VERSION "2027-draft-2026-10-23"

NS_ :

BS_:

BU_: Blackbody1 Blackbody2 Blackbody3 ChassisIMU MIKA StrainGaugeFront StrainGaugeRear SuspensionFL SuspensionFR SuspensionRear UprightFL UprightFR UprightRear
VAL_TABLE_ EnableDisable 1 "Enabled" 0 "Disabled" ;
VAL_TABLE_ OnOff 1 "On" 0 "Off" ;
VAL_TABLE_ FaultState 1 "Fault" 0 "OK" ;
VAL_TABLE_ WarningState 1 "Warning" 0 "NoWarning" ;
VAL_TABLE_ DeviceStatus 2 "Waiting" 1 "Fault" 0 "OK" ;
VAL_TABLE_ Permission 1 "Allowed" 0 "NotAllowed" ;
VAL_TABLE_ Connection 1 "Connected" 0 "Disconnected" ;
VAL_TABLE_ ServerConnection 1 "Connected" 0 "Disconnected/Retrying" ;
VAL_TABLE_ Pressed 1 "Pressed" 0 "NotPressed" ;
VAL_TABLE_ Validity 1 "Valid" 0 "Invalid" ;
VAL_TABLE_ Watchdog 1 "TimedOut" 0 "Alive" ;
VAL_TABLE_ NormalAdvanced 1 "Advanced" 0 "Normal" ;
VAL_TABLE_ MotorCommandSource 1 "External" 0 "VCU" ;
VAL_TABLE_ Gear 3 "Invalid" 2 "Reverse" 1 "Forward" 0 "Neutral" ;
VAL_TABLE_ BPSFaultSummary 5 "SMBFault" 4 "PrechargeFault" 3 "ContactorRelayFault" 2 "EmergencyStop" 1 "SetpointFault" 0 "OK" ;
VAL_TABLE_ VCUState 7 "VehicleNotReady" 6 "Disabled" 5 "CruiseControl" 4 "Regen" 3 "ReverseDrive" 2 "NeutralDrive" 1 "ForwardDrive" 0 "Init" ;
VAL_TABLE_ ChargeState 2 "Charging" 1 "Standby" 0 "Disabled" ;
VAL_TABLE_ EVSEState 5 "F_EVSEFault" 4 "E_Fault" 3 "D_VentilationRequired" 2 "C_ChargingReady" 1 "B_Connected" 0 "A_Disconnected" ;
VAL_TABLE_ GPSAntennaState 3 "Unknown" 2 "ShortCircuit" 1 "OpenCircuit" 0 "OK" ;
VAL_TABLE_ GPSFix 2 "Fix3D" 1 "Fix2D" 0 "NoFix" ;
VAL_TABLE_ CellularTechnology 4 "Other" 3 "NB_IoT" 2 "LTE_M" 1 "LTE" 0 "None" ;
VAL_TABLE_ TPEEControlMode 2 "ConstantInputVoltage" 1 "PerturbAndObserve" 0 "Disabled" ;
VAL_TABLE_ TPEEOperatingMode 7 "Fault" 6 "MinimumInputVoltage" 5 "TemperatureDerating" 4 "ConstantOutputCurrent" 3 "ConstantOutputVoltage" 2 "MinimumInputCurrent" 1 "ConstantInputCurrent" 0 "ConstantInputVoltage" ;
VAL_TABLE_ TPEEFault 8 "Fault" 7 "PhaseOverCurrent" 6 "InputUnderCurrent" 5 "InputOverCurrent" 4 "OutputOverCurrent" 3 "OutputOverVoltage" 2 "InputOverVoltage" 1 "ConfigurationError" 0 "OK" ;
VAL_TABLE_ LWSCalibration 1 "Calibrated" 0 "NotCalibrated" ;
VAL_TABLE_ LWSTrim 1 "Trimmed" 0 "NotTrimmed" ;
VAL_TABLE_ LWSCommand 5 "ResetCalibration" 3 "SetAngleZero" ;
VAL_TABLE_ ElconControl 1 "Disable" 0 "Charge" ;
VAL_TABLE_ ElconMuxPage 5 "Page5" 4 "Page4" 3 "Page3" 2 "Page2" 1 "Page1" ;

BO_ 1568 TimestampSync: 2 MIKA
 SG_ Timestamp : 0|16@1+ (1,0) [0|65535] "" Vector__XXX

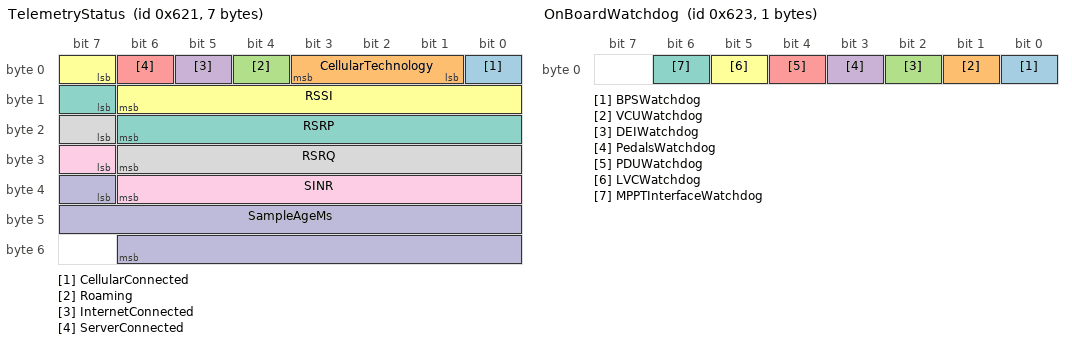
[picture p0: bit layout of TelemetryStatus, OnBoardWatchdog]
BO_ 1569 TelemetryStatus: 7 MIKA
 SG_ CellularConnected : 0|1@1+ (1,0) [0.0|1.0] "" Vector__XXX
 SG_ CellularTechnology : 1|3@1+ (1,0) [0.0|7.0] "" Vector__XXX
 SG_ Roaming : 4|1@1+ (1,0) [0.0|1.0] "" Vector__XXX
 SG_ InternetConnected : 5|1@1+ (1,0) [0.0|1.0] "" Vector__XXX
 SG_ ServerConnected : 6|1@1+ (1,0) [0|1] "" Vector__XXX
 SG_ RSSI : 7|8@1- (1,0) [-128.0|127.0] "dBm" Vector__XXX
 SG_ RSRP : 15|8@1- (1,0) [-128.0|127.0] "dBm" Vector__XXX
 SG_ RSRQ : 23|8@1- (0.5,0) [-64.0|63.5] "dB" Vector__XXX
 SG_ SINR : 31|8@1- (0.5,0) [-64.0|63.5] "dB" Vector__XXX
 SG_ SampleAgeMs : 39|16@1+ (1,0) [0|65535] "ms" Vector__XXX

BO_ 1570 GPSData: 20 MIKA
 SG_ GPSAntennaState : 0|2@1+ (1,0) [0.0|3.0] "" Vector__XXX
 SG_ GPSFix : 2|2@1+ (1,0) [0.0|3.0] "" Vector__XXX
 SG_ GPSLongitude : 4|32@1- (1e-06,0) [-180|180] "deg" Vector__XXX
 SG_ GPSLatitude : 36|32@1- (1e-06,0) [-90|90] "deg" Vector__XXX
 SG_ GPSSpeed : 68|16@1+ (0.01,0) [0.0|655.35] "m/s" Vector__XXX
 SG_ GPSHeading : 84|16@1+ (0.01,0) [0|359.99] "deg" Vector__XXX
 SG_ GPSAltitude : 100|16@1- (0.1,0) [-3276.8|3276.7] "m" Vector__XXX
 SG_ SatellitesInUse : 116|8@1+ (1,0) [0.0|255.0] "" Vector__XXX
 SG_ SampleAgeMs : 124|16@1+ (1,0) [0|65535] "ms" Vector__XXX

BO_ 1571 OnBoardWatchdog: 1 MIKA
 SG_ BPSWatchdog : 0|1@1+ (1,0) [0.0|1.0] "" Vector__XXX
 SG_ VCUWatchdog : 1|1@1+ (1,0) [0.0|1.0] "" Vector__XXX
 SG_ DEIWatchdog : 2|1@1+ (1,0) [0.0|1.0] "" Vector__XXX
 SG_ PedalsWatchdog : 3|1@1+ (1,0) [0.0|1.0] "" Vector__XXX
 SG_ PDUWatchdog : 4|1@1+ (1,0) [0.0|1.0] "" Vector__XXX
 SG_ LVCWatchdog : 5|1@1+ (1,0) [0.0|1.0] "" Vector__XXX
 SG_ MPPTInterfaceWatchdog : 6|1@1+ (1,0) [0.0|1.0] "" Vector__XXX

BO_ 1584 ChassisAccelerationData: 32 ChassisIMU
 SG_ Timestamp : 0|16@1+ (1,0) [0|65535] "" Vector__XXX
 SG_ SampleIntervalTicks : 16|16@1+ (1,0) [1|65535.0] "" Vector__XXX
 SG_ AccelerationX1 : 32|13@1- (0.001,0) [-4.096|4.095] "g" Vector__XXX
 SG_ AccelerationX2 : 45|13@1- (0.001,0) [-4.096|4.095] "g" Vector__XXX
 SG_ AccelerationX3 : 58|13@1- (0.001,0) [-4.096|4.095] "g" Vector__XXX
 SG_ AccelerationX4 : 71|13@1- (0.001,0) [-4.096|4.095] "g" Vector__XXX
 SG_ AccelerationXAverage : 84|13@1- (0.001,0) [-4.096|4.095] "g" Vector__XXX
 SG_ AccelerationY1 : 97|13@1- (0.001,0) [-4.096|4.095] "g" Vector__XXX
 SG_ AccelerationY2 : 110|13@1- (0.001,0) [-4.096|4.095] "g" Vector__XXX
 SG_ AccelerationY3 : 123|13@1- (0.001,0) [-4.096|4.095] "g" Vector__XXX
 SG_ AccelerationY4 : 136|13@1- (0.001,0) [-4.096|4.095] "g" Vector__XXX
 SG_ AccelerationYAverage : 149|13@1- (0.001,0) [-4.096|4.095] "g" Vector__XXX
 SG_ AccelerationZ1 : 162|13@1- (0.001,0) [-4.096|4.095] "g" Vector__XXX
 SG_ AccelerationZ2 : 175|13@1- (0.001,0) [-4.096|4.095] "g" Vector__XXX
 SG_ AccelerationZ3 : 188|13@1- (0.001,0) [-4.096|4.095] "g" Vector__XXX
 SG_ AccelerationZ4 : 201|13@1- (0.001,0) [-4.096|4.095] "g" Vector__XXX
 SG_ AccelerationZAverage : 214|13@1- (0.001,0) [-4.096|4.095] "g" Vector__XXX
 SG_ SampleAgeMs : 227|16@1+ (1,0) [0|65535] "ms" Vector__XXX

BO_ 1585 ChassisGyroData: 48 ChassisIMU
 SG_ Timestamp : 0|16@1+ (1,0) [0|65535] "" Vector__XXX
 SG_ SampleIntervalTicks : 16|16@1+ (1,0) [1|65535.0] "" Vector__XXX
 SG_ GyroX1 : 32|16@1- (0.02,0) [-655.36|655.34] "deg/s" Vector__XXX
 SG_ GyroX2 : 48|16@1- (0.02,0) [-655.36|655.34] "deg/s" Vector__XXX
 SG_ GyroX3 : 64|16@1- (0.02,0) [-655.36|655.34] "deg/s" Vector__XXX
 SG_ GyroX4 : 80|16@1- (0.02,0) [-655.36|655.34] "deg/s" Vector__XXX
 SG_ GyroXAverage : 96|16@1- (0.02,0) [-655.36|655.34] "deg/s" Vector__XXX
 SG_ GyroY1 : 112|16@1- (0.02,0) [-655.36|655.34] "deg/s" Vector__XXX
 SG_ GyroY2 : 128|16@1- (0.02,0) [-655.36|655.34] "deg/s" Vector__XXX
 SG_ GyroY3 : 144|16@1- (0.02,0) [-655.36|655.34] "deg/s" Vector__XXX
 SG_ GyroY4 : 160|16@1- (0.02,0) [-655.36|655.34] "deg/s" Vector__XXX
 SG_ GyroYAverage : 176|16@1- (0.02,0) [-655.36|655.34] "deg/s" Vector__XXX
 SG_ GyroZ1 : 192|16@1- (0.02,0) [-655.36|655.34] "deg/s" Vector__XXX
 SG_ GyroZ2 : 208|16@1- (0.02,0) [-655.36|655.34] "deg/s" Vector__XXX
 SG_ GyroZ3 : 224|16@1- (0.02,0) [-655.36|655.34] "deg/s" Vector__XXX
 SG_ GyroZ4 : 240|16@1- (0.02,0) [-655.36|655.34] "deg/s" Vector__XXX
 SG_ GyroZAverage : 256|16@1- (0.02,0) [-655.36|655.34] "deg/s" Vector__XXX
 SG_ SampleAgeMs : 272|16@1+ (1,0) [0|65535] "ms" Vector__XXX

BO_ 1586 ChassisMagnetometerData: 32 ChassisIMU
 SG_ Timestamp : 0|16@1+ (1,0) [0|65535] "" Vector__XXX
 SG_ SampleIntervalTicks : 16|16@1+ (1,0) [1|65535.0] "" Vector__XXX
 SG_ MagneticFieldX1 : 32|12@1- (0.15,0) [-307.2|307.05] "uT" Vector__XXX
 SG_ MagneticFieldX2 : 44|12@1- (0.15,0) [-307.2|307.05] "uT" Vector__XXX
 SG_ MagneticFieldX3 : 56|12@1- (0.15,0) [-307.2|307.05] "uT" Vector__XXX
 SG_ MagneticFieldX4 : 68|12@1- (0.15,0) [-307.2|307.05] "uT" Vector__XXX
 SG_ MagneticFieldXAverage : 80|12@1- (0.15,0) [-307.2|307.05] "uT" Vector__XXX
 SG_ MagneticFieldY1 : 92|12@1- (0.15,0) [-307.2|307.05] "uT" Vector__XXX
 SG_ MagneticFieldY2 : 104|12@1- (0.15,0) [-307.2|307.05] "uT" Vector__XXX
 SG_ MagneticFieldY3 : 116|12@1- (0.15,0) [-307.2|307.05] "uT" Vector__XXX
 SG_ MagneticFieldY4 : 128|12@1- (0.15,0) [-307.2|307.05] "uT" Vector__XXX
 SG_ MagneticFieldYAverage : 140|12@1- (0.15,0) [-307.2|307.05] "uT" Vector__XXX
 SG_ MagneticFieldZ1 : 152|12@1- (0.15,0) [-307.2|307.05] "uT" Vector__XXX
 SG_ MagneticFieldZ2 : 164|12@1- (0.15,0) [-307.2|307.05] "uT" Vector__XXX
 SG_ MagneticFieldZ3 : 176|12@1- (0.15,0) [-307.2|307.05] "uT" Vector__XXX
 SG_ MagneticFieldZ4 : 188|12@1- (0.15,0) [-307.2|307.05] "uT" Vector__XXX
 SG_ MagneticFieldZAverage : 200|12@1- (0.15,0) [-307.2|307.05] "uT" Vector__XXX
 SG_ SampleAgeMs : 212|16@1+ (1,0) [0|65535] "ms" Vector__XXX

BO_ 1600 UprightFRAccelerationData: 48 UprightFR
 SG_ Timestamp : 0|16@1+ (1,0) [0|65535] "" Vector__XXX
 SG_ SampleIntervalTicks : 16|16@1+ (1,0) [1|65535.0] "" Vector__XXX
 SG_ AccelerationX1 : 32|15@1- (0.001,0) [-16.384|16.383] "g" Vector__XXX
 SG_ AccelerationX2 : 47|15@1- (0.001,0) [-16.384|16.383] "g" Vector__XXX
 SG_ AccelerationX3 : 62|15@1- (0.001,0) [-16.384|16.383] "g" Vector__XXX
 SG_ AccelerationX4 : 77|15@1- (0.001,0) [-16.384|16.383] "g" Vector__XXX
 SG_ AccelerationXAverage : 92|15@1- (0.001,0) [-16.384|16.383] "g" Vector__XXX
 SG_ AccelerationY1 : 107|15@1- (0.001,0) [-16.384|16.383] "g" Vector__XXX
 SG_ AccelerationY2 : 122|15@1- (0.001,0) [-16.384|16.383] "g" Vector__XXX
 SG_ AccelerationY3 : 137|15@1- (0.001,0) [-16.384|16.383] "g" Vector__XXX
 SG_ AccelerationY4 : 152|15@1- (0.001,0) [-16.384|16.383] "g" Vector__XXX
 SG_ AccelerationYAverage : 167|15@1- (0.001,0) [-16.384|16.383] "g" Vector__XXX
 SG_ AccelerationZ1 : 182|15@1- (0.001,0) [-16.384|16.383] "g" Vector__XXX
 SG_ AccelerationZ2 : 197|15@1- (0.001,0) [-16.384|16.383] "g" Vector__XXX
 SG_ AccelerationZ3 : 212|15@1- (0.001,0) [-16.384|16.383] "g" Vector__XXX
 SG_ AccelerationZ4 : 227|15@1- (0.001,0) [-16.384|16.383] "g" Vector__XXX
 SG_ AccelerationZAverage : 242|15@1- (0.001,0) [-16.384|16.383] "g" Vector__XXX
 SG_ SampleAgeMs : 257|16@1+ (1,0) [0|65535] "ms" Vector__XXX

BO_ 1601 UprightFRGyroData: 48 UprightFR
 SG_ Timestamp : 0|16@1+ (1,0) [0|65535] "" Vector__XXX
 SG_ SampleIntervalTicks : 16|16@1+ (1,0) [1|65535.0] "" Vector__XXX
 SG_ GyroX1 : 32|16@1- (0.02,0) [-655.36|655.34] "deg/s" Vector__XXX
 SG_ GyroX2 : 48|16@1- (0.02,0) [-655.36|655.34] "deg/s" Vector__XXX
 SG_ GyroX3 : 64|16@1- (0.02,0) [-655.36|655.34] "deg/s" Vector__XXX
 SG_ GyroX4 : 80|16@1- (0.02,0) [-655.36|655.34] "deg/s" Vector__XXX
 SG_ GyroXAverage : 96|16@1- (0.02,0) [-655.36|655.34] "deg/s" Vector__XXX
 SG_ GyroY1 : 112|16@1- (0.02,0) [-655.36|655.34] "deg/s" Vector__XXX
 SG_ GyroY2 : 128|16@1- (0.02,0) [-655.36|655.34] "deg/s" Vector__XXX
 SG_ GyroY3 : 144|16@1- (0.02,0) [-655.36|655.34] "deg/s" Vector__XXX
 SG_ GyroY4 : 160|16@1- (0.02,0) [-655.36|655.34] "deg/s" Vector__XXX
 SG_ GyroYAverage : 176|16@1- (0.02,0) [-655.36|655.34] "deg/s" Vector__XXX
 SG_ GyroZ1 : 192|16@1- (0.02,0) [-655.36|655.34] "deg/s" Vector__XXX
 SG_ GyroZ2 : 208|16@1- (0.02,0) [-655.36|655.34] "deg/s" Vector__XXX
 SG_ GyroZ3 : 224|16@1- (0.02,0) [-655.36|655.34] "deg/s" Vector__XXX
 SG_ GyroZ4 : 240|16@1- (0.02,0) [-655.36|655.34] "deg/s" Vector__XXX
 SG_ GyroZAverage : 256|16@1- (0.02,0) [-655.36|655.34] "deg/s" Vector__XXX
 SG_ SampleAgeMs : 272|16@1+ (1,0) [0|65535] "ms" Vector__XXX

BO_ 1602 UprightFRWheelSpeedData: 16 UprightFR
 SG_ Timestamp : 0|16@1+ (1,0) [0|65535] "" Vector__XXX
 SG_ SampleIntervalTicks : 16|16@1+ (1,0) [1|65535.0] "" Vector__XXX
 SG_ WheelRPM1 : 32|12@1+ (0.5,0) [0.0|2047.5] "rpm" Vector__XXX
 SG_ WheelRPM2 : 44|12@1+ (0.5,0) [0.0|2047.5] "rpm" Vector__XXX
 SG_ WheelRPM3 : 56|12@1+ (0.5,0) [0.0|2047.5] "rpm" Vector__XXX
 SG_ WheelRPM4 : 68|12@1+ (0.5,0) [0.0|2047.5] "rpm" Vector__XXX
 SG_ WheelRPMAverage : 80|12@1+ (0.5,0) [0.0|2047.5] "rpm" Vector__XXX
 SG_ SampleAgeMs : 92|16@1+ (1,0) [0|65535] "ms" Vector__XXX

BO_ 1616 UprightFLAccelerationData: 48 UprightFL
 SG_ Timestamp : 0|16@1+ (1,0) [0|65535] "" Vector__XXX
 SG_ SampleIntervalTicks : 16|16@1+ (1,0) [1|65535.0] "" Vector__XXX
 SG_ AccelerationX1 : 32|15@1- (0.001,0) [-16.384|16.383] "g" Vector__XXX
 SG_ AccelerationX2 : 47|15@1- (0.001,0) [-16.384|16.383] "g" Vector__XXX
 SG_ AccelerationX3 : 62|15@1- (0.001,0) [-16.384|16.383] "g" Vector__XXX
 SG_ AccelerationX4 : 77|15@1- (0.001,0) [-16.384|16.383] "g" Vector__XXX
 SG_ AccelerationXAverage : 92|15@1- (0.001,0) [-16.384|16.383] "g" Vector__XXX
 SG_ AccelerationY1 : 107|15@1- (0.001,0) [-16.384|16.383] "g" Vector__XXX
 SG_ AccelerationY2 : 122|15@1- (0.001,0) [-16.384|16.383] "g" Vector__XXX
 SG_ AccelerationY3 : 137|15@1- (0.001,0) [-16.384|16.383] "g" Vector__XXX
 SG_ AccelerationY4 : 152|15@1- (0.001,0) [-16.384|16.383] "g" Vector__XXX
 SG_ AccelerationYAverage : 167|15@1- (0.001,0) [-16.384|16.383] "g" Vector__XXX
 SG_ AccelerationZ1 : 182|15@1- (0.001,0) [-16.384|16.383] "g" Vector__XXX
 SG_ AccelerationZ2 : 197|15@1- (0.001,0) [-16.384|16.383] "g" Vector__XXX
 SG_ AccelerationZ3 : 212|15@1- (0.001,0) [-16.384|16.383] "g" Vector__XXX
 SG_ AccelerationZ4 : 227|15@1- (0.001,0) [-16.384|16.383] "g" Vector__XXX
 SG_ AccelerationZAverage : 242|15@1- (0.001,0) [-16.384|16.383] "g" Vector__XXX
 SG_ SampleAgeMs : 257|16@1+ (1,0) [0|65535] "ms" Vector__XXX

BO_ 1617 UprightFLGyroData: 48 UprightFL
 SG_ Timestamp : 0|16@1+ (1,0) [0|65535] "" Vector__XXX
 SG_ SampleIntervalTicks : 16|16@1+ (1,0) [1|65535.0] "" Vector__XXX
 SG_ GyroX1 : 32|16@1- (0.02,0) [-655.36|655.34] "deg/s" Vector__XXX
 SG_ GyroX2 : 48|16@1- (0.02,0) [-655.36|655.34] "deg/s" Vector__XXX
 SG_ GyroX3 : 64|16@1- (0.02,0) [-655.36|655.34] "deg/s" Vector__XXX
 SG_ GyroX4 : 80|16@1- (0.02,0) [-655.36|655.34] "deg/s" Vector__XXX
 SG_ GyroXAverage : 96|16@1- (0.02,0) [-655.36|655.34] "deg/s" Vector__XXX
 SG_ GyroY1 : 112|16@1- (0.02,0) [-655.36|655.34] "deg/s" Vector__XXX
 SG_ GyroY2 : 128|16@1- (0.02,0) [-655.36|655.34] "deg/s" Vector__XXX
 SG_ GyroY3 : 144|16@1- (0.02,0) [-655.36|655.34] "deg/s" Vector__XXX
 SG_ GyroY4 : 160|16@1- (0.02,0) [-655.36|655.34] "deg/s" Vector__XXX
 SG_ GyroYAverage : 176|16@1- (0.02,0) [-655.36|655.34] "deg/s" Vector__XXX
 SG_ GyroZ1 : 192|16@1- (0.02,0) [-655.36|655.34] "deg/s" Vector__XXX
 SG_ GyroZ2 : 208|16@1- (0.02,0) [-655.36|655.34] "deg/s" Vector__XXX
 SG_ GyroZ3 : 224|16@1- (0.02,0) [-655.36|655.34] "deg/s" Vector__XXX
 SG_ GyroZ4 : 240|16@1- (0.02,0) [-655.36|655.34] "deg/s" Vector__XXX
 SG_ GyroZAverage : 256|16@1- (0.02,0) [-655.36|655.34] "deg/s" Vector__XXX
 SG_ SampleAgeMs : 272|16@1+ (1,0) [0|65535] "ms" Vector__XXX

BO_ 1618 UprightFLWheelSpeedData: 16 UprightFL
 SG_ Timestamp : 0|16@1+ (1,0) [0|65535] "" Vector__XXX
 SG_ SampleIntervalTicks : 16|16@1+ (1,0) [1|65535.0] "" Vector__XXX
 SG_ WheelRPM1 : 32|12@1+ (0.5,0) [0.0|2047.5] "rpm" Vector__XXX
 SG_ WheelRPM2 : 44|12@1+ (0.5,0) [0.0|2047.5] "rpm" Vector__XXX
 SG_ WheelRPM3 : 56|12@1+ (0.5,0) [0.0|2047.5] "rpm" Vector__XXX
 SG_ WheelRPM4 : 68|12@1+ (0.5,0) [0.0|2047.5] "rpm" Vector__XXX
 SG_ WheelRPMAverage : 80|12@1+ (0.5,0) [0.0|2047.5] "rpm" Vector__XXX
 SG_ SampleAgeMs : 92|16@1+ (1,0) [0|65535] "ms" Vector__XXX

BO_ 1632 UprightRearAccelerationData: 48 UprightRear
 SG_ Timestamp : 0|16@1+ (1,0) [0|65535] "" Vector__XXX
 SG_ SampleIntervalTicks : 16|16@1+ (1,0) [1|65535.0] "" Vector__XXX
 SG_ AccelerationX1 : 32|15@1- (0.001,0) [-16.384|16.383] "g" Vector__XXX
 SG_ AccelerationX2 : 47|15@1- (0.001,0) [-16.384|16.383] "g" Vector__XXX
 SG_ AccelerationX3 : 62|15@1- (0.001,0) [-16.384|16.383] "g" Vector__XXX
 SG_ AccelerationX4 : 77|15@1- (0.001,0) [-16.384|16.383] "g" Vector__XXX
 SG_ AccelerationXAverage : 92|15@1- (0.001,0) [-16.384|16.383] "g" Vector__XXX
 SG_ AccelerationY1 : 107|15@1- (0.001,0) [-16.384|16.383] "g" Vector__XXX
 SG_ AccelerationY2 : 122|15@1- (0.001,0) [-16.384|16.383] "g" Vector__XXX
 SG_ AccelerationY3 : 137|15@1- (0.001,0) [-16.384|16.383] "g" Vector__XXX
 SG_ AccelerationY4 : 152|15@1- (0.001,0) [-16.384|16.383] "g" Vector__XXX
 SG_ AccelerationYAverage : 167|15@1- (0.001,0) [-16.384|16.383] "g" Vector__XXX
 SG_ AccelerationZ1 : 182|15@1- (0.001,0) [-16.384|16.383] "g" Vector__XXX
 SG_ AccelerationZ2 : 197|15@1- (0.001,0) [-16.384|16.383] "g" Vector__XXX
 SG_ AccelerationZ3 : 212|15@1- (0.001,0) [-16.384|16.383] "g" Vector__XXX
 SG_ AccelerationZ4 : 227|15@1- (0.001,0) [-16.384|16.383] "g" Vector__XXX
 SG_ AccelerationZAverage : 242|15@1- (0.001,0) [-16.384|16.383] "g" Vector__XXX
 SG_ SampleAgeMs : 257|16@1+ (1,0) [0|65535] "ms" Vector__XXX

BO_ 1633 UprightRearGyroData: 48 UprightRear
 SG_ Timestamp : 0|16@1+ (1,0) [0|65535] "" Vector__XXX
 SG_ SampleIntervalTicks : 16|16@1+ (1,0) [1|65535.0] "" Vector__XXX
 SG_ GyroX1 : 32|16@1- (0.02,0) [-655.36|655.34] "deg/s" Vector__XXX
 SG_ GyroX2 : 48|16@1- (0.02,0) [-655.36|655.34] "deg/s" Vector__XXX
 SG_ GyroX3 : 64|16@1- (0.02,0) [-655.36|655.34] "deg/s" Vector__XXX
 SG_ GyroX4 : 80|16@1- (0.02,0) [-655.36|655.34] "deg/s" Vector__XXX
 SG_ GyroXAverage : 96|16@1- (0.02,0) [-655.36|655.34] "deg/s" Vector__XXX
 SG_ GyroY1 : 112|16@1- (0.02,0) [-655.36|655.34] "deg/s" Vector__XXX
 SG_ GyroY2 : 128|16@1- (0.02,0) [-655.36|655.34] "deg/s" Vector__XXX
 SG_ GyroY3 : 144|16@1- (0.02,0) [-655.36|655.34] "deg/s" Vector__XXX
 SG_ GyroY4 : 160|16@1- (0.02,0) [-655.36|655.34] "deg/s" Vector__XXX
 SG_ GyroYAverage : 176|16@1- (0.02,0) [-655.36|655.34] "deg/s" Vector__XXX
 SG_ GyroZ1 : 192|16@1- (0.02,0) [-655.36|655.34] "deg/s" Vector__XXX
 SG_ GyroZ2 : 208|16@1- (0.02,0) [-655.36|655.34] "deg/s" Vector__XXX
 SG_ GyroZ3 : 224|16@1- (0.02,0) [-655.36|655.34] "deg/s" Vector__XXX
 SG_ GyroZ4 : 240|16@1- (0.02,0) [-655.36|655.34] "deg/s" Vector__XXX
 SG_ GyroZAverage : 256|16@1- (0.02,0) [-655.36|655.34] "deg/s" Vector__XXX
 SG_ SampleAgeMs : 272|16@1+ (1,0) [0|65535] "ms" Vector__XXX

BO_ 1634 UprightRearWheelSpeedData: 16 UprightRear
 SG_ Timestamp : 0|16@1+ (1,0) [0|65535] "" Vector__XXX
 SG_ SampleIntervalTicks : 16|16@1+ (1,0) [1|65535.0] "" Vector__XXX
 SG_ WheelRPM1 : 32|12@1+ (0.5,0) [0.0|2047.5] "rpm" Vector__XXX
 SG_ WheelRPM2 : 44|12@1+ (0.5,0) [0.0|2047.5] "rpm" Vector__XXX
 SG_ WheelRPM3 : 56|12@1+ (0.5,0) [0.0|2047.5] "rpm" Vector__XXX
 SG_ WheelRPM4 : 68|12@1+ (0.5,0) [0.0|2047.5] "rpm" Vector__XXX
 SG_ WheelRPMAverage : 80|12@1+ (0.5,0) [0.0|2047.5] "rpm" Vector__XXX
 SG_ SampleAgeMs : 92|16@1+ (1,0) [0|65535] "ms" Vector__XXX

BO_ 1648 SuspensionFRData: 12 SuspensionFR
 SG_ Timestamp : 0|16@1+ (1,0) [0|65535] "" Vector__XXX
 SG_ LinpotPosition1 : 16|12@1+ (0.0188885,1) [1|78.3494075] "mm" Vector__XXX
 SG_ LinpotPosition2 : 28|12@1+ (0.0188885,1) [1|78.3494075] "mm" Vector__XXX
 SG_ LinpotPosition3 : 40|12@1+ (0.0188885,1) [1|78.3494075] "mm" Vector__XXX
 SG_ LinpotPosition4 : 52|12@1+ (0.0188885,1) [1|78.3494075] "mm" Vector__XXX
 SG_ LinpotPositionAverage : 64|12@1+ (0.0188885,1) [1|78.3494075] "mm" Vector__XXX
 SG_ SampleAgeMs : 76|16@1+ (1,0) [0|65535] "ms" Vector__XXX

BO_ 1649 SuspensionFLData: 12 SuspensionFL
 SG_ Timestamp : 0|16@1+ (1,0) [0|65535] "" Vector__XXX
 SG_ LinpotPosition1 : 16|12@1+ (0.0188885,1) [1|78.3494075] "mm" Vector__XXX
 SG_ LinpotPosition2 : 28|12@1+ (0.0188885,1) [1|78.3494075] "mm" Vector__XXX
 SG_ LinpotPosition3 : 40|12@1+ (0.0188885,1) [1|78.3494075] "mm" Vector__XXX
 SG_ LinpotPosition4 : 52|12@1+ (0.0188885,1) [1|78.3494075] "mm" Vector__XXX
 SG_ LinpotPositionAverage : 64|12@1+ (0.0188885,1) [1|78.3494075] "mm" Vector__XXX
 SG_ SampleAgeMs : 76|16@1+ (1,0) [0|65535] "ms" Vector__XXX

BO_ 1650 SuspensionRearData: 12 SuspensionRear
 SG_ Timestamp : 0|16@1+ (1,0) [0|65535] "" Vector__XXX
 SG_ LinpotPosition1 : 16|12@1+ (0.0188885,1) [1|78.3494075] "mm" Vector__XXX
 SG_ LinpotPosition2 : 28|12@1+ (0.0188885,1) [1|78.3494075] "mm" Vector__XXX
 SG_ LinpotPosition3 : 40|12@1+ (0.0188885,1) [1|78.3494075] "mm" Vector__XXX
 SG_ LinpotPosition4 : 52|12@1+ (0.0188885,1) [1|78.3494075] "mm" Vector__XXX
 SG_ LinpotPositionAverage : 64|12@1+ (0.0188885,1) [1|78.3494075] "mm" Vector__XXX
 SG_ SampleAgeMs : 76|16@1+ (1,0) [0|65535] "ms" Vector__XXX

BO_ 1664 Blackbody1Data: 0 Blackbody1

BO_ 1665 Blackbody2Data: 0 Blackbody2

BO_ 1666 Blackbody3Data: 0 Blackbody3

BO_ 1680 StrainGaugeFrontData: 0 StrainGaugeFront

BO_ 1681 StrainGaugeRearData: 0 StrainGaugeRear

CM_ BO_ 1568 "MIKA timestamp synchronization: legacy two-byte unsigned little-endian raw count. New allocation ID 0x620 and CAN-FD retained; time unit/epoch/period are not specified.";
CM_ SG_ 1568 Timestamp "Legacy unsigned 16-bit raw time count. Tick period and epoch are unresolved; do not interpret as milliseconds or seconds. Wraps modulo 65536 ticks.";
CM_ BO_ 1569 "2027 team-defined layout; physical values use the shared scaling conventions.";
CM_ SG_ 1569 SampleAgeMs "Age in milliseconds of the oldest continuous sensor sample included in this frame when assembled; saturates at 65535. Age must advance for cached samples. In a fault snapshot, freeze age at fault detection; per-channel captured ages, if present, remain authoritative for individual trip records.";
CM_ SG_ 1569 SINR "SINR";
CM_ SG_ 1569 RSRQ "RSRQ";
CM_ SG_ 1569 RSRP "RSRP";
CM_ SG_ 1569 RSSI "RSSI";
CM_ SG_ 1569 ServerConnected "Connection to the telemetry server; independent of internet connectivity.";
CM_ SG_ 1569 InternetConnected "InternetConnected";
CM_ SG_ 1569 Roaming "Roaming";
CM_ SG_ 1569 CellularTechnology "CellularTechnology";
CM_ SG_ 1569 CellularConnected "CellularConnected";
CM_ BO_ 1570 "GPS receiver state and measurements. SampleAgeMs is the age of the oldest included GPS measurement, saturated at 65535 ms.";
CM_ SG_ 1570 SampleAgeMs "Age in milliseconds of the oldest continuous sensor sample included in this frame when assembled; saturates at 65535. Age must advance for cached samples. In a fault snapshot, freeze age at fault detection; per-channel captured ages, if present, remain authoritative for individual trip records.";
CM_ SG_ 1570 SatellitesInUse "SatellitesInUse";
CM_ SG_ 1570 GPSAltitude "GPSAltitude";
CM_ SG_ 1570 GPSHeading "GPSHeading";
CM_ SG_ 1570 GPSSpeed "GPSSpeed";
CM_ SG_ 1570 GPSLatitude "GPSLatitude";
CM_ SG_ 1570 GPSLongitude "Longitude range corrected from swapped draft coordinates.";
CM_ SG_ 1570 GPSFix "GPSFix";
CM_ SG_ 1570 GPSAntennaState "GPSAntennaState";
CM_ BO_ 1571 "MIKA reports watchdog state of other boards: 0 alive, 1 timed out. Former MIKA self-watchdog removed; bit 7 is reserved.";
CM_ SG_ 1571 MPPTInterfaceWatchdog "MPPTInterfaceWatchdog";
CM_ SG_ 1571 LVCWatchdog "LVCWatchdog";
CM_ SG_ 1571 PDUWatchdog "PDUWatchdog";
CM_ SG_ 1571 PedalsWatchdog "PedalsWatchdog";
CM_ SG_ 1571 DEIWatchdog "DEIWatchdog";
CM_ SG_ 1571 VCUWatchdog "VCUWatchdog";
CM_ SG_ 1571 BPSWatchdog "BPSWatchdog";
CM_ BO_ 1584 "Four chronological samples per axis/value and their sender-computed averages. Little-endian CAN-FD; raw timestamp/interval tick duration remains unresolved. Emit only four valid samples, do not substitute stale/invalid values. Each sensor modality has its own sampling interval; magnetometer batches need not align with IMU batches. Sensor saturation must be handled by firmware.";
CM_ SG_ 1584 SampleAgeMs "Age in milliseconds of the oldest continuous sensor sample included in this frame when assembled; saturates at 65535. Age must advance for cached samples. In a fault snapshot, freeze age at fault detection; per-channel captured ages, if present, remain authoritative for individual trip records.";
CM_ SG_ 1584 AccelerationZAverage "Sender-populated arithmetic mean of AccelerationZ1..AccelerationZ4. Round to nearest wire step, exact ties away from zero in raw space. Codec does not compute this field.";
CM_ SG_ 1584 AccelerationZ4 "Chronological sample 4 of AccelerationZ; indices 1..4 align across axes within this batch. Physical unit g.";
CM_ SG_ 1584 AccelerationZ3 "Chronological sample 3 of AccelerationZ; indices 1..4 align across axes within this batch. Physical unit g.";
CM_ SG_ 1584 AccelerationZ2 "Chronological sample 2 of AccelerationZ; indices 1..4 align across axes within this batch. Physical unit g.";
CM_ SG_ 1584 AccelerationZ1 "Chronological sample 1 of AccelerationZ; indices 1..4 align across axes within this batch. Physical unit g.";
CM_ SG_ 1584 AccelerationYAverage "Sender-populated arithmetic mean of AccelerationY1..AccelerationY4. Round to nearest wire step, exact ties away from zero in raw space. Codec does not compute this field.";
CM_ SG_ 1584 AccelerationY4 "Chronological sample 4 of AccelerationY; indices 1..4 align across axes within this batch. Physical unit g.";
CM_ SG_ 1584 AccelerationY3 "Chronological sample 3 of AccelerationY; indices 1..4 align across axes within this batch. Physical unit g.";
CM_ SG_ 1584 AccelerationY2 "Chronological sample 2 of AccelerationY; indices 1..4 align across axes within this batch. Physical unit g.";
CM_ SG_ 1584 AccelerationY1 "Chronological sample 1 of AccelerationY; indices 1..4 align across axes within this batch. Physical unit g.";
CM_ SG_ 1584 AccelerationXAverage "Sender-populated arithmetic mean of AccelerationX1..AccelerationX4. Round to nearest wire step, exact ties away from zero in raw space. Codec does not compute this field.";
CM_ SG_ 1584 AccelerationX4 "Chronological sample 4 of AccelerationX; indices 1..4 align across axes within this batch. Physical unit g.";
CM_ SG_ 1584 AccelerationX3 "Chronological sample 3 of AccelerationX; indices 1..4 align across axes within this batch. Physical unit g.";
CM_ SG_ 1584 AccelerationX2 "Chronological sample 2 of AccelerationX; indices 1..4 align across axes within this batch. Physical unit g.";
CM_ SG_ 1584 AccelerationX1 "Chronological sample 1 of AccelerationX; indices 1..4 align across axes within this batch. Physical unit g.";
CM_ SG_ 1584 SampleIntervalTicks "Uniform interval between samples 1..4, in the same unresolved ticks as Timestamp. Must be positive; send only complete four-sample batches. Matching accel/gyro batches from one board share timing.";
CM_ SG_ 1584 Timestamp "Time count of sample 1. Same unresolved raw tick timebase as TimestampSync; wraps modulo 65536 ticks.";
CM_ BO_ 1585 "Four chronological samples per axis/value and their sender-computed averages. Little-endian CAN-FD; raw timestamp/interval tick duration remains unresolved. Emit only four valid samples, do not substitute stale/invalid values. Each sensor modality has its own sampling interval; magnetometer batches need not align with IMU batches. Sensor saturation must be handled by firmware.";
CM_ SG_ 1585 SampleAgeMs "Age in milliseconds of the oldest continuous sensor sample included in this frame when assembled; saturates at 65535. Age must advance for cached samples. In a fault snapshot, freeze age at fault detection; per-channel captured ages, if present, remain authoritative for individual trip records.";
CM_ SG_ 1585 GyroZAverage "Sender-populated arithmetic mean of GyroZ1..GyroZ4. Round to nearest wire step, exact ties away from zero in raw space. Codec does not compute this field.";
CM_ SG_ 1585 GyroZ4 "Chronological sample 4 of GyroZ; indices 1..4 align across axes within this batch. Physical unit deg/s.";
CM_ SG_ 1585 GyroZ3 "Chronological sample 3 of GyroZ; indices 1..4 align across axes within this batch. Physical unit deg/s.";
CM_ SG_ 1585 GyroZ2 "Chronological sample 2 of GyroZ; indices 1..4 align across axes within this batch. Physical unit deg/s.";
CM_ SG_ 1585 GyroZ1 "Chronological sample 1 of GyroZ; indices 1..4 align across axes within this batch. Physical unit deg/s.";
CM_ SG_ 1585 GyroYAverage "Sender-populated arithmetic mean of GyroY1..GyroY4. Round to nearest wire step, exact ties away from zero in raw space. Codec does not compute this field.";
CM_ SG_ 1585 GyroY4 "Chronological sample 4 of GyroY; indices 1..4 align across axes within this batch. Physical unit deg/s.";
CM_ SG_ 1585 GyroY3 "Chronological sample 3 of GyroY; indices 1..4 align across axes within this batch. Physical unit deg/s.";
CM_ SG_ 1585 GyroY2 "Chronological sample 2 of GyroY; indices 1..4 align across axes within this batch. Physical unit deg/s.";
CM_ SG_ 1585 GyroY1 "Chronological sample 1 of GyroY; indices 1..4 align across axes within this batch. Physical unit deg/s.";
CM_ SG_ 1585 GyroXAverage "Sender-populated arithmetic mean of GyroX1..GyroX4. Round to nearest wire step, exact ties away from zero in raw space. Codec does not compute this field.";
CM_ SG_ 1585 GyroX4 "Chronological sample 4 of GyroX; indices 1..4 align across axes within this batch. Physical unit deg/s.";
CM_ SG_ 1585 GyroX3 "Chronological sample 3 of GyroX; indices 1..4 align across axes within this batch. Physical unit deg/s.";
CM_ SG_ 1585 GyroX2 "Chronological sample 2 of GyroX; indices 1..4 align across axes within this batch. Physical unit deg/s.";
CM_ SG_ 1585 GyroX1 "Chronological sample 1 of GyroX; indices 1..4 align across axes within this batch. Physical unit deg/s.";
CM_ SG_ 1585 SampleIntervalTicks "Uniform interval between samples 1..4, in the same unresolved ticks as Timestamp. Must be positive; send only complete four-sample batches. Matching accel/gyro batches from one board share timing.";
CM_ SG_ 1585 Timestamp "Time count of sample 1. Same unresolved raw tick timebase as TimestampSync; wraps modulo 65536 ticks.";
CM_ BO_ 1586 "Four chronological samples per axis/value and their sender-computed averages. Little-endian CAN-FD; raw timestamp/interval tick duration remains unresolved. Emit only four valid samples, do not substitute stale/invalid values. Each sensor modality has its own sampling interval; magnetometer batches need not align with IMU batches. Sensor saturation must be handled by firmware.";
CM_ SG_ 1586 SampleAgeMs "Age in milliseconds of the oldest continuous sensor sample included in this frame when assembled; saturates at 65535. Age must advance for cached samples. In a fault snapshot, freeze age at fault detection; per-channel captured ages, if present, remain authoritative for individual trip records.";
CM_ SG_ 1586 MagneticFieldZAverage "Sender-populated arithmetic mean of MagneticFieldZ1..MagneticFieldZ4. Round to nearest wire step, exact ties away from zero in raw space. Codec does not compute this field.";
CM_ SG_ 1586 MagneticFieldZ4 "Chronological sample 4 of MagneticFieldZ; indices 1..4 align across axes within this batch. Physical unit uT.";
CM_ SG_ 1586 MagneticFieldZ3 "Chronological sample 3 of MagneticFieldZ; indices 1..4 align across axes within this batch. Physical unit uT.";
CM_ SG_ 1586 MagneticFieldZ2 "Chronological sample 2 of MagneticFieldZ; indices 1..4 align across axes within this batch. Physical unit uT.";
CM_ SG_ 1586 MagneticFieldZ1 "Chronological sample 1 of MagneticFieldZ; indices 1..4 align across axes within this batch. Physical unit uT.";
CM_ SG_ 1586 MagneticFieldYAverage "Sender-populated arithmetic mean of MagneticFieldY1..MagneticFieldY4. Round to nearest wire step, exact ties away from zero in raw space. Codec does not compute this field.";
CM_ SG_ 1586 MagneticFieldY4 "Chronological sample 4 of MagneticFieldY; indices 1..4 align across axes within this batch. Physical unit uT.";
CM_ SG_ 1586 MagneticFieldY3 "Chronological sample 3 of MagneticFieldY; indices 1..4 align across axes within this batch. Physical unit uT.";
CM_ SG_ 1586 MagneticFieldY2 "Chronological sample 2 of MagneticFieldY; indices 1..4 align across axes within this batch. Physical unit uT.";
CM_ SG_ 1586 MagneticFieldY1 "Chronological sample 1 of MagneticFieldY; indices 1..4 align across axes within this batch. Physical unit uT.";
CM_ SG_ 1586 MagneticFieldXAverage "Sender-populated arithmetic mean of MagneticFieldX1..MagneticFieldX4. Round to nearest wire step, exact ties away from zero in raw space. Codec does not compute this field.";
CM_ SG_ 1586 MagneticFieldX4 "Chronological sample 4 of MagneticFieldX; indices 1..4 align across axes within this batch. Physical unit uT.";
CM_ SG_ 1586 MagneticFieldX3 "Chronological sample 3 of MagneticFieldX; indices 1..4 align across axes within this batch. Physical unit uT.";
CM_ SG_ 1586 MagneticFieldX2 "Chronological sample 2 of MagneticFieldX; indices 1..4 align across axes within this batch. Physical unit uT.";
CM_ SG_ 1586 MagneticFieldX1 "Chronological sample 1 of MagneticFieldX; indices 1..4 align across axes within this batch. Physical unit uT.";
CM_ SG_ 1586 SampleIntervalTicks "Uniform interval between samples 1..4, in the same unresolved ticks as Timestamp. Must be positive; send only complete four-sample batches. Matching accel/gyro batches from one board share timing.";
CM_ SG_ 1586 Timestamp "Time count of sample 1. Same unresolved raw tick timebase as TimestampSync; wraps modulo 65536 ticks.";
CM_ BO_ 1600 "Four chronological samples per axis/value and their sender-computed averages. Little-endian CAN-FD; raw timestamp/interval tick duration remains unresolved. Emit only four valid samples, do not substitute stale/invalid values. Each sensor modality has its own sampling interval; magnetometer batches need not align with IMU batches. Sensor saturation must be handled by firmware.";
CM_ SG_ 1600 SampleAgeMs "Age in milliseconds of the oldest continuous sensor sample included in this frame when assembled; saturates at 65535. Age must advance for cached samples. In a fault snapshot, freeze age at fault detection; per-channel captured ages, if present, remain authoritative for individual trip records.";
CM_ SG_ 1600 AccelerationZAverage "Sender-populated arithmetic mean of AccelerationZ1..AccelerationZ4. Round to nearest wire step, exact ties away from zero in raw space. Codec does not compute this field.";
CM_ SG_ 1600 AccelerationZ4 "Chronological sample 4 of AccelerationZ; indices 1..4 align across axes within this batch. Physical unit g.";
CM_ SG_ 1600 AccelerationZ3 "Chronological sample 3 of AccelerationZ; indices 1..4 align across axes within this batch. Physical unit g.";
CM_ SG_ 1600 AccelerationZ2 "Chronological sample 2 of AccelerationZ; indices 1..4 align across axes within this batch. Physical unit g.";
CM_ SG_ 1600 AccelerationZ1 "Chronological sample 1 of AccelerationZ; indices 1..4 align across axes within this batch. Physical unit g.";
CM_ SG_ 1600 AccelerationYAverage "Sender-populated arithmetic mean of AccelerationY1..AccelerationY4. Round to nearest wire step, exact ties away from zero in raw space. Codec does not compute this field.";
CM_ SG_ 1600 AccelerationY4 "Chronological sample 4 of AccelerationY; indices 1..4 align across axes within this batch. Physical unit g.";
CM_ SG_ 1600 AccelerationY3 "Chronological sample 3 of AccelerationY; indices 1..4 align across axes within this batch. Physical unit g.";
CM_ SG_ 1600 AccelerationY2 "Chronological sample 2 of AccelerationY; indices 1..4 align across axes within this batch. Physical unit g.";
CM_ SG_ 1600 AccelerationY1 "Chronological sample 1 of AccelerationY; indices 1..4 align across axes within this batch. Physical unit g.";
CM_ SG_ 1600 AccelerationXAverage "Sender-populated arithmetic mean of AccelerationX1..AccelerationX4. Round to nearest wire step, exact ties away from zero in raw space. Codec does not compute this field.";
CM_ SG_ 1600 AccelerationX4 "Chronological sample 4 of AccelerationX; indices 1..4 align across axes within this batch. Physical unit g.";
CM_ SG_ 1600 AccelerationX3 "Chronological sample 3 of AccelerationX; indices 1..4 align across axes within this batch. Physical unit g.";
CM_ SG_ 1600 AccelerationX2 "Chronological sample 2 of AccelerationX; indices 1..4 align across axes within this batch. Physical unit g.";
CM_ SG_ 1600 AccelerationX1 "Chronological sample 1 of AccelerationX; indices 1..4 align across axes within this batch. Physical unit g.";
CM_ SG_ 1600 SampleIntervalTicks "Uniform interval between samples 1..4, in the same unresolved ticks as Timestamp. Must be positive; send only complete four-sample batches. Matching accel/gyro batches from one board share timing.";
CM_ SG_ 1600 Timestamp "Time count of sample 1. Same unresolved raw tick timebase as TimestampSync; wraps modulo 65536 ticks.";
CM_ BO_ 1601 "Four chronological samples per axis/value and their sender-computed averages. Little-endian CAN-FD; raw timestamp/interval tick duration remains unresolved. Emit only four valid samples, do not substitute stale/invalid values. Each sensor modality has its own sampling interval; magnetometer batches need not align with IMU batches. Sensor saturation must be handled by firmware.";
CM_ SG_ 1601 SampleAgeMs "Age in milliseconds of the oldest continuous sensor sample included in this frame when assembled; saturates at 65535. Age must advance for cached samples. In a fault snapshot, freeze age at fault detection; per-channel captured ages, if present, remain authoritative for individual trip records.";
CM_ SG_ 1601 GyroZAverage "Sender-populated arithmetic mean of GyroZ1..GyroZ4. Round to nearest wire step, exact ties away from zero in raw space. Codec does not compute this field.";
CM_ SG_ 1601 GyroZ4 "Chronological sample 4 of GyroZ; indices 1..4 align across axes within this batch. Physical unit deg/s.";
CM_ SG_ 1601 GyroZ3 "Chronological sample 3 of GyroZ; indices 1..4 align across axes within this batch. Physical unit deg/s.";
CM_ SG_ 1601 GyroZ2 "Chronological sample 2 of GyroZ; indices 1..4 align across axes within this batch. Physical unit deg/s.";
CM_ SG_ 1601 GyroZ1 "Chronological sample 1 of GyroZ; indices 1..4 align across axes within this batch. Physical unit deg/s.";
CM_ SG_ 1601 GyroYAverage "Sender-populated arithmetic mean of GyroY1..GyroY4. Round to nearest wire step, exact ties away from zero in raw space. Codec does not compute this field.";
CM_ SG_ 1601 GyroY4 "Chronological sample 4 of GyroY; indices 1..4 align across axes within this batch. Physical unit deg/s.";
CM_ SG_ 1601 GyroY3 "Chronological sample 3 of GyroY; indices 1..4 align across axes within this batch. Physical unit deg/s.";
CM_ SG_ 1601 GyroY2 "Chronological sample 2 of GyroY; indices 1..4 align across axes within this batch. Physical unit deg/s.";
CM_ SG_ 1601 GyroY1 "Chronological sample 1 of GyroY; indices 1..4 align across axes within this batch. Physical unit deg/s.";
CM_ SG_ 1601 GyroXAverage "Sender-populated arithmetic mean of GyroX1..GyroX4. Round to nearest wire step, exact ties away from zero in raw space. Codec does not compute this field.";
CM_ SG_ 1601 GyroX4 "Chronological sample 4 of GyroX; indices 1..4 align across axes within this batch. Physical unit deg/s.";
CM_ SG_ 1601 GyroX3 "Chronological sample 3 of GyroX; indices 1..4 align across axes within this batch. Physical unit deg/s.";
CM_ SG_ 1601 GyroX2 "Chronological sample 2 of GyroX; indices 1..4 align across axes within this batch. Physical unit deg/s.";
CM_ SG_ 1601 GyroX1 "Chronological sample 1 of GyroX; indices 1..4 align across axes within this batch. Physical unit deg/s.";
CM_ SG_ 1601 SampleIntervalTicks "Uniform interval between samples 1..4, in the same unresolved ticks as Timestamp. Must be positive; send only complete four-sample batches. Matching accel/gyro batches from one board share timing.";
CM_ SG_ 1601 Timestamp "Time count of sample 1. Same unresolved raw tick timebase as TimestampSync; wraps modulo 65536 ticks.";
CM_ BO_ 1602 "Four chronological samples per axis/value and their sender-computed averages. Little-endian CAN-FD; raw timestamp/interval tick duration remains unresolved. Emit only four valid samples, do not substitute stale/invalid values. Each sensor modality has its own sampling interval; magnetometer batches need not align with IMU batches. Sensor saturation must be handled by firmware.";
CM_ SG_ 1602 SampleAgeMs "Age in milliseconds of the oldest continuous sensor sample included in this frame when assembled; saturates at 65535. Age must advance for cached samples. In a fault snapshot, freeze age at fault detection; per-channel captured ages, if present, remain authoritative for individual trip records.";
CM_ SG_ 1602 WheelRPMAverage "Sender-populated arithmetic mean of WheelRPM1..WheelRPM4. Round to nearest wire step, exact ties away from zero in raw space. Codec does not compute this field.";
CM_ SG_ 1602 WheelRPM4 "Chronological sample 4 of WheelRPM; indices 1..4 align across axes within this batch. Physical unit rpm.";
CM_ SG_ 1602 WheelRPM3 "Chronological sample 3 of WheelRPM; indices 1..4 align across axes within this batch. Physical unit rpm.";
CM_ SG_ 1602 WheelRPM2 "Chronological sample 2 of WheelRPM; indices 1..4 align across axes within this batch. Physical unit rpm.";
CM_ SG_ 1602 WheelRPM1 "Chronological sample 1 of WheelRPM; indices 1..4 align across axes within this batch. Physical unit rpm.";
CM_ SG_ 1602 SampleIntervalTicks "Uniform interval between samples 1..4, in the same unresolved ticks as Timestamp. Must be positive; send only complete four-sample batches. Matching accel/gyro batches from one board share timing.";
CM_ SG_ 1602 Timestamp "Time count of sample 1. Same unresolved raw tick timebase as TimestampSync; wraps modulo 65536 ticks.";
CM_ BO_ 1616 "Four chronological samples per axis/value and their sender-computed averages. Little-endian CAN-FD; raw timestamp/interval tick duration remains unresolved. Emit only four valid samples, do not substitute stale/invalid values. Each sensor modality has its own sampling interval; magnetometer batches need not align with IMU batches. Sensor saturation must be handled by firmware.";
CM_ SG_ 1616 SampleAgeMs "Age in milliseconds of the oldest continuous sensor sample included in this frame when assembled; saturates at 65535. Age must advance for cached samples. In a fault snapshot, freeze age at fault detection; per-channel captured ages, if present, remain authoritative for individual trip records.";
CM_ SG_ 1616 AccelerationZAverage "Sender-populated arithmetic mean of AccelerationZ1..AccelerationZ4. Round to nearest wire step, exact ties away from zero in raw space. Codec does not compute this field.";
CM_ SG_ 1616 AccelerationZ4 "Chronological sample 4 of AccelerationZ; indices 1..4 align across axes within this batch. Physical unit g.";
CM_ SG_ 1616 AccelerationZ3 "Chronological sample 3 of AccelerationZ; indices 1..4 align across axes within this batch. Physical unit g.";
CM_ SG_ 1616 AccelerationZ2 "Chronological sample 2 of AccelerationZ; indices 1..4 align across axes within this batch. Physical unit g.";
CM_ SG_ 1616 AccelerationZ1 "Chronological sample 1 of AccelerationZ; indices 1..4 align across axes within this batch. Physical unit g.";
CM_ SG_ 1616 AccelerationYAverage "Sender-populated arithmetic mean of AccelerationY1..AccelerationY4. Round to nearest wire step, exact ties away from zero in raw space. Codec does not compute this field.";
CM_ SG_ 1616 AccelerationY4 "Chronological sample 4 of AccelerationY; indices 1..4 align across axes within this batch. Physical unit g.";
CM_ SG_ 1616 AccelerationY3 "Chronological sample 3 of AccelerationY; indices 1..4 align across axes within this batch. Physical unit g.";
CM_ SG_ 1616 AccelerationY2 "Chronological sample 2 of AccelerationY; indices 1..4 align across axes within this batch. Physical unit g.";
CM_ SG_ 1616 AccelerationY1 "Chronological sample 1 of AccelerationY; indices 1..4 align across axes within this batch. Physical unit g.";
CM_ SG_ 1616 AccelerationXAverage "Sender-populated arithmetic mean of AccelerationX1..AccelerationX4. Round to nearest wire step, exact ties away from zero in raw space. Codec does not compute this field.";
CM_ SG_ 1616 AccelerationX4 "Chronological sample 4 of AccelerationX; indices 1..4 align across axes within this batch. Physical unit g.";
CM_ SG_ 1616 AccelerationX3 "Chronological sample 3 of AccelerationX; indices 1..4 align across axes within this batch. Physical unit g.";
CM_ SG_ 1616 AccelerationX2 "Chronological sample 2 of AccelerationX; indices 1..4 align across axes within this batch. Physical unit g.";
CM_ SG_ 1616 AccelerationX1 "Chronological sample 1 of AccelerationX; indices 1..4 align across axes within this batch. Physical unit g.";
CM_ SG_ 1616 SampleIntervalTicks "Uniform interval between samples 1..4, in the same unresolved ticks as Timestamp. Must be positive; send only complete four-sample batches. Matching accel/gyro batches from one board share timing.";
CM_ SG_ 1616 Timestamp "Time count of sample 1. Same unresolved raw tick timebase as TimestampSync; wraps modulo 65536 ticks.";
CM_ BO_ 1617 "Four chronological samples per axis/value and their sender-computed averages. Little-endian CAN-FD; raw timestamp/interval tick duration remains unresolved. Emit only four valid samples, do not substitute stale/invalid values. Each sensor modality has its own sampling interval; magnetometer batches need not align with IMU batches. Sensor saturation must be handled by firmware.";
CM_ SG_ 1617 SampleAgeMs "Age in milliseconds of the oldest continuous sensor sample included in this frame when assembled; saturates at 65535. Age must advance for cached samples. In a fault snapshot, freeze age at fault detection; per-channel captured ages, if present, remain authoritative for individual trip records.";
CM_ SG_ 1617 GyroZAverage "Sender-populated arithmetic mean of GyroZ1..GyroZ4. Round to nearest wire step, exact ties away from zero in raw space. Codec does not compute this field.";
CM_ SG_ 1617 GyroZ4 "Chronological sample 4 of GyroZ; indices 1..4 align across axes within this batch. Physical unit deg/s.";
CM_ SG_ 1617 GyroZ3 "Chronological sample 3 of GyroZ; indices 1..4 align across axes within this batch. Physical unit deg/s.";
CM_ SG_ 1617 GyroZ2 "Chronological sample 2 of GyroZ; indices 1..4 align across axes within this batch. Physical unit deg/s.";
CM_ SG_ 1617 GyroZ1 "Chronological sample 1 of GyroZ; indices 1..4 align across axes within this batch. Physical unit deg/s.";
CM_ SG_ 1617 GyroYAverage "Sender-populated arithmetic mean of GyroY1..GyroY4. Round to nearest wire step, exact ties away from zero in raw space. Codec does not compute this field.";
CM_ SG_ 1617 GyroY4 "Chronological sample 4 of GyroY; indices 1..4 align across axes within this batch. Physical unit deg/s.";
CM_ SG_ 1617 GyroY3 "Chronological sample 3 of GyroY; indices 1..4 align across axes within this batch. Physical unit deg/s.";
CM_ SG_ 1617 GyroY2 "Chronological sample 2 of GyroY; indices 1..4 align across axes within this batch. Physical unit deg/s.";
CM_ SG_ 1617 GyroY1 "Chronological sample 1 of GyroY; indices 1..4 align across axes within this batch. Physical unit deg/s.";
CM_ SG_ 1617 GyroXAverage "Sender-populated arithmetic mean of GyroX1..GyroX4. Round to nearest wire step, exact ties away from zero in raw space. Codec does not compute this field.";
CM_ SG_ 1617 GyroX4 "Chronological sample 4 of GyroX; indices 1..4 align across axes within this batch. Physical unit deg/s.";
CM_ SG_ 1617 GyroX3 "Chronological sample 3 of GyroX; indices 1..4 align across axes within this batch. Physical unit deg/s.";
CM_ SG_ 1617 GyroX2 "Chronological sample 2 of GyroX; indices 1..4 align across axes within this batch. Physical unit deg/s.";
CM_ SG_ 1617 GyroX1 "Chronological sample 1 of GyroX; indices 1..4 align across axes within this batch. Physical unit deg/s.";
CM_ SG_ 1617 SampleIntervalTicks "Uniform interval between samples 1..4, in the same unresolved ticks as Timestamp. Must be positive; send only complete four-sample batches. Matching accel/gyro batches from one board share timing.";
CM_ SG_ 1617 Timestamp "Time count of sample 1. Same unresolved raw tick timebase as TimestampSync; wraps modulo 65536 ticks.";
CM_ BO_ 1618 "Four chronological samples per axis/value and their sender-computed averages. Little-endian CAN-FD; raw timestamp/interval tick duration remains unresolved. Emit only four valid samples, do not substitute stale/invalid values. Each sensor modality has its own sampling interval; magnetometer batches need not align with IMU batches. Sensor saturation must be handled by firmware.";
CM_ SG_ 1618 SampleAgeMs "Age in milliseconds of the oldest continuous sensor sample included in this frame when assembled; saturates at 65535. Age must advance for cached samples. In a fault snapshot, freeze age at fault detection; per-channel captured ages, if present, remain authoritative for individual trip records.";
CM_ SG_ 1618 WheelRPMAverage "Sender-populated arithmetic mean of WheelRPM1..WheelRPM4. Round to nearest wire step, exact ties away from zero in raw space. Codec does not compute this field.";
CM_ SG_ 1618 WheelRPM4 "Chronological sample 4 of WheelRPM; indices 1..4 align across axes within this batch. Physical unit rpm.";
CM_ SG_ 1618 WheelRPM3 "Chronological sample 3 of WheelRPM; indices 1..4 align across axes within this batch. Physical unit rpm.";
CM_ SG_ 1618 WheelRPM2 "Chronological sample 2 of WheelRPM; indices 1..4 align across axes within this batch. Physical unit rpm.";
CM_ SG_ 1618 WheelRPM1 "Chronological sample 1 of WheelRPM; indices 1..4 align across axes within this batch. Physical unit rpm.";
CM_ SG_ 1618 SampleIntervalTicks "Uniform interval between samples 1..4, in the same unresolved ticks as Timestamp. Must be positive; send only complete four-sample batches. Matching accel/gyro batches from one board share timing.";
CM_ SG_ 1618 Timestamp "Time count of sample 1. Same unresolved raw tick timebase as TimestampSync; wraps modulo 65536 ticks.";
CM_ BO_ 1632 "Four chronological samples per axis/value and their sender-computed averages. Little-endian CAN-FD; raw timestamp/interval tick duration remains unresolved. Emit only four valid samples, do not substitute stale/invalid values. Each sensor modality has its own sampling interval; magnetometer batches need not align with IMU batches. Sensor saturation must be handled by firmware.";
CM_ SG_ 1632 SampleAgeMs "Age in milliseconds of the oldest continuous sensor sample included in this frame when assembled; saturates at 65535. Age must advance for cached samples. In a fault snapshot, freeze age at fault detection; per-channel captured ages, if present, remain authoritative for individual trip records.";
CM_ SG_ 1632 AccelerationZAverage "Sender-populated arithmetic mean of AccelerationZ1..AccelerationZ4. Round to nearest wire step, exact ties away from zero in raw space. Codec does not compute this field.";
CM_ SG_ 1632 AccelerationZ4 "Chronological sample 4 of AccelerationZ; indices 1..4 align across axes within this batch. Physical unit g.";
CM_ SG_ 1632 AccelerationZ3 "Chronological sample 3 of AccelerationZ; indices 1..4 align across axes within this batch. Physical unit g.";
CM_ SG_ 1632 AccelerationZ2 "Chronological sample 2 of AccelerationZ; indices 1..4 align across axes within this batch. Physical unit g.";
CM_ SG_ 1632 AccelerationZ1 "Chronological sample 1 of AccelerationZ; indices 1..4 align across axes within this batch. Physical unit g.";
CM_ SG_ 1632 AccelerationYAverage "Sender-populated arithmetic mean of AccelerationY1..AccelerationY4. Round to nearest wire step, exact ties away from zero in raw space. Codec does not compute this field.";
CM_ SG_ 1632 AccelerationY4 "Chronological sample 4 of AccelerationY; indices 1..4 align across axes within this batch. Physical unit g.";
CM_ SG_ 1632 AccelerationY3 "Chronological sample 3 of AccelerationY; indices 1..4 align across axes within this batch. Physical unit g.";
CM_ SG_ 1632 AccelerationY2 "Chronological sample 2 of AccelerationY; indices 1..4 align across axes within this batch. Physical unit g.";
CM_ SG_ 1632 AccelerationY1 "Chronological sample 1 of AccelerationY; indices 1..4 align across axes within this batch. Physical unit g.";
CM_ SG_ 1632 AccelerationXAverage "Sender-populated arithmetic mean of AccelerationX1..AccelerationX4. Round to nearest wire step, exact ties away from zero in raw space. Codec does not compute this field.";
CM_ SG_ 1632 AccelerationX4 "Chronological sample 4 of AccelerationX; indices 1..4 align across axes within this batch. Physical unit g.";
CM_ SG_ 1632 AccelerationX3 "Chronological sample 3 of AccelerationX; indices 1..4 align across axes within this batch. Physical unit g.";
CM_ SG_ 1632 AccelerationX2 "Chronological sample 2 of AccelerationX; indices 1..4 align across axes within this batch. Physical unit g.";
CM_ SG_ 1632 AccelerationX1 "Chronological sample 1 of AccelerationX; indices 1..4 align across axes within this batch. Physical unit g.";
CM_ SG_ 1632 SampleIntervalTicks "Uniform interval between samples 1..4, in the same unresolved ticks as Timestamp. Must be positive; send only complete four-sample batches. Matching accel/gyro batches from one board share timing.";
CM_ SG_ 1632 Timestamp "Time count of sample 1. Same unresolved raw tick timebase as TimestampSync; wraps modulo 65536 ticks.";
CM_ BO_ 1633 "Four chronological samples per axis/value and their sender-computed averages. Little-endian CAN-FD; raw timestamp/interval tick duration remains unresolved. Emit only four valid samples, do not substitute stale/invalid values. Each sensor modality has its own sampling interval; magnetometer batches need not align with IMU batches. Sensor saturation must be handled by firmware.";
CM_ SG_ 1633 SampleAgeMs "Age in milliseconds of the oldest continuous sensor sample included in this frame when assembled; saturates at 65535. Age must advance for cached samples. In a fault snapshot, freeze age at fault detection; per-channel captured ages, if present, remain authoritative for individual trip records.";
CM_ SG_ 1633 GyroZAverage "Sender-populated arithmetic mean of GyroZ1..GyroZ4. Round to nearest wire step, exact ties away from zero in raw space. Codec does not compute this field.";
CM_ SG_ 1633 GyroZ4 "Chronological sample 4 of GyroZ; indices 1..4 align across axes within this batch. Physical unit deg/s.";
CM_ SG_ 1633 GyroZ3 "Chronological sample 3 of GyroZ; indices 1..4 align across axes within this batch. Physical unit deg/s.";
CM_ SG_ 1633 GyroZ2 "Chronological sample 2 of GyroZ; indices 1..4 align across axes within this batch. Physical unit deg/s.";
CM_ SG_ 1633 GyroZ1 "Chronological sample 1 of GyroZ; indices 1..4 align across axes within this batch. Physical unit deg/s.";
CM_ SG_ 1633 GyroYAverage "Sender-populated arithmetic mean of GyroY1..GyroY4. Round to nearest wire step, exact ties away from zero in raw space. Codec does not compute this field.";
CM_ SG_ 1633 GyroY4 "Chronological sample 4 of GyroY; indices 1..4 align across axes within this batch. Physical unit deg/s.";
CM_ SG_ 1633 GyroY3 "Chronological sample 3 of GyroY; indices 1..4 align across axes within this batch. Physical unit deg/s.";
CM_ SG_ 1633 GyroY2 "Chronological sample 2 of GyroY; indices 1..4 align across axes within this batch. Physical unit deg/s.";
CM_ SG_ 1633 GyroY1 "Chronological sample 1 of GyroY; indices 1..4 align across axes within this batch. Physical unit deg/s.";
CM_ SG_ 1633 GyroXAverage "Sender-populated arithmetic mean of GyroX1..GyroX4. Round to nearest wire step, exact ties away from zero in raw space. Codec does not compute this field.";
CM_ SG_ 1633 GyroX4 "Chronological sample 4 of GyroX; indices 1..4 align across axes within this batch. Physical unit deg/s.";
CM_ SG_ 1633 GyroX3 "Chronological sample 3 of GyroX; indices 1..4 align across axes within this batch. Physical unit deg/s.";
CM_ SG_ 1633 GyroX2 "Chronological sample 2 of GyroX; indices 1..4 align across axes within this batch. Physical unit deg/s.";
CM_ SG_ 1633 GyroX1 "Chronological sample 1 of GyroX; indices 1..4 align across axes within this batch. Physical unit deg/s.";
CM_ SG_ 1633 SampleIntervalTicks "Uniform interval between samples 1..4, in the same unresolved ticks as Timestamp. Must be positive; send only complete four-sample batches. Matching accel/gyro batches from one board share timing.";
CM_ SG_ 1633 Timestamp "Time count of sample 1. Same unresolved raw tick timebase as TimestampSync; wraps modulo 65536 ticks.";
CM_ BO_ 1634 "Four chronological samples per axis/value and their sender-computed averages. Little-endian CAN-FD; raw timestamp/interval tick duration remains unresolved. Emit only four valid samples, do not substitute stale/invalid values. Each sensor modality has its own sampling interval; magnetometer batches need not align with IMU batches. Sensor saturation must be handled by firmware.";
CM_ SG_ 1634 SampleAgeMs "Age in milliseconds of the oldest continuous sensor sample included in this frame when assembled; saturates at 65535. Age must advance for cached samples. In a fault snapshot, freeze age at fault detection; per-channel captured ages, if present, remain authoritative for individual trip records.";
CM_ SG_ 1634 WheelRPMAverage "Sender-populated arithmetic mean of WheelRPM1..WheelRPM4. Round to nearest wire step, exact ties away from zero in raw space. Codec does not compute this field.";
CM_ SG_ 1634 WheelRPM4 "Chronological sample 4 of WheelRPM; indices 1..4 align across axes within this batch. Physical unit rpm.";
CM_ SG_ 1634 WheelRPM3 "Chronological sample 3 of WheelRPM; indices 1..4 align across axes within this batch. Physical unit rpm.";
CM_ SG_ 1634 WheelRPM2 "Chronological sample 2 of WheelRPM; indices 1..4 align across axes within this batch. Physical unit rpm.";
CM_ SG_ 1634 WheelRPM1 "Chronological sample 1 of WheelRPM; indices 1..4 align across axes within this batch. Physical unit rpm.";
CM_ SG_ 1634 SampleIntervalTicks "Uniform interval between samples 1..4, in the same unresolved ticks as Timestamp. Must be positive; send only complete four-sample batches. Matching accel/gyro batches from one board share timing.";
CM_ SG_ 1634 Timestamp "Time count of sample 1. Same unresolved raw tick timebase as TimestampSync; wraps modulo 65536 ticks.";
CM_ BO_ 1648 "Four simultaneous physical linpot channels, plus their sender-computed arithmetic mean. Legacy 16-bit raw timestamp and 12-bit ADC calibration retained; all little-endian. The average extends the payload from 8 to 12 bytes. The four channels are not chronological samples.";
CM_ SG_ 1648 SampleAgeMs "Age in milliseconds of the oldest continuous sensor sample included in this frame when assembled; saturates at 65535. Age must advance for cached samples. In a fault snapshot, freeze age at fault detection; per-channel captured ages, if present, remain authoritative for individual trip records.";
CM_ SG_ 1648 LinpotPositionAverage "Sender-populated arithmetic mean of LinpotPosition1..4 in mm. Same scale/offset as individual channels: average the four raw ADC counts, round to nearest raw count (half upward), then apply mm = raw * 0.0188885 + 1. Codec does not compute this field.";
CM_ SG_ 1648 LinpotPosition4 "Legacy linpot calibration: wire raw is 12-bit ADC count (0..4095); physical mm = raw * 0.0188885 + 1. Same sensor/measuring scheme as last year.";
CM_ SG_ 1648 LinpotPosition3 "Legacy linpot calibration: wire raw is 12-bit ADC count (0..4095); physical mm = raw * 0.0188885 + 1. Same sensor/measuring scheme as last year.";
CM_ SG_ 1648 LinpotPosition2 "Legacy linpot calibration: wire raw is 12-bit ADC count (0..4095); physical mm = raw * 0.0188885 + 1. Same sensor/measuring scheme as last year.";
CM_ SG_ 1648 LinpotPosition1 "Legacy linpot calibration: wire raw is 12-bit ADC count (0..4095); physical mm = raw * 0.0188885 + 1. Same sensor/measuring scheme as last year.";
CM_ SG_ 1648 Timestamp "Legacy unsigned 16-bit raw time count. Tick period and epoch are unresolved; do not interpret as milliseconds or seconds. Wraps modulo 65536 ticks.";
CM_ BO_ 1649 "Four simultaneous physical linpot channels, plus their sender-computed arithmetic mean. Legacy 16-bit raw timestamp and 12-bit ADC calibration retained; all little-endian. The average extends the payload from 8 to 12 bytes. The four channels are not chronological samples.";
CM_ SG_ 1649 SampleAgeMs "Age in milliseconds of the oldest continuous sensor sample included in this frame when assembled; saturates at 65535. Age must advance for cached samples. In a fault snapshot, freeze age at fault detection; per-channel captured ages, if present, remain authoritative for individual trip records.";
CM_ SG_ 1649 LinpotPositionAverage "Sender-populated arithmetic mean of LinpotPosition1..4 in mm. Same scale/offset as individual channels: average the four raw ADC counts, round to nearest raw count (half upward), then apply mm = raw * 0.0188885 + 1. Codec does not compute this field.";
CM_ SG_ 1649 LinpotPosition4 "Legacy linpot calibration: wire raw is 12-bit ADC count (0..4095); physical mm = raw * 0.0188885 + 1. Same sensor/measuring scheme as last year.";
CM_ SG_ 1649 LinpotPosition3 "Legacy linpot calibration: wire raw is 12-bit ADC count (0..4095); physical mm = raw * 0.0188885 + 1. Same sensor/measuring scheme as last year.";
CM_ SG_ 1649 LinpotPosition2 "Legacy linpot calibration: wire raw is 12-bit ADC count (0..4095); physical mm = raw * 0.0188885 + 1. Same sensor/measuring scheme as last year.";
CM_ SG_ 1649 LinpotPosition1 "Legacy linpot calibration: wire raw is 12-bit ADC count (0..4095); physical mm = raw * 0.0188885 + 1. Same sensor/measuring scheme as last year.";
CM_ SG_ 1649 Timestamp "Legacy unsigned 16-bit raw time count. Tick period and epoch are unresolved; do not interpret as milliseconds or seconds. Wraps modulo 65536 ticks.";
CM_ BO_ 1650 "Four simultaneous physical linpot channels, plus their sender-computed arithmetic mean. Legacy 16-bit raw timestamp and 12-bit ADC calibration retained; all little-endian. The average extends the payload from 8 to 12 bytes. The four channels are not chronological samples.";
CM_ SG_ 1650 SampleAgeMs "Age in milliseconds of the oldest continuous sensor sample included in this frame when assembled; saturates at 65535. Age must advance for cached samples. In a fault snapshot, freeze age at fault detection; per-channel captured ages, if present, remain authoritative for individual trip records.";
CM_ SG_ 1650 LinpotPositionAverage "Sender-populated arithmetic mean of LinpotPosition1..4 in mm. Same scale/offset as individual channels: average the four raw ADC counts, round to nearest raw count (half upward), then apply mm = raw * 0.0188885 + 1. Codec does not compute this field.";
CM_ SG_ 1650 LinpotPosition4 "Legacy linpot calibration: wire raw is 12-bit ADC count (0..4095); physical mm = raw * 0.0188885 + 1. Same sensor/measuring scheme as last year.";
CM_ SG_ 1650 LinpotPosition3 "Legacy linpot calibration: wire raw is 12-bit ADC count (0..4095); physical mm = raw * 0.0188885 + 1. Same sensor/measuring scheme as last year.";
CM_ SG_ 1650 LinpotPosition2 "Legacy linpot calibration: wire raw is 12-bit ADC count (0..4095); physical mm = raw * 0.0188885 + 1. Same sensor/measuring scheme as last year.";
CM_ SG_ 1650 LinpotPosition1 "Legacy linpot calibration: wire raw is 12-bit ADC count (0..4095); physical mm = raw * 0.0188885 + 1. Same sensor/measuring scheme as last year.";
CM_ SG_ 1650 Timestamp "Legacy unsigned 16-bit raw time count. Tick period and epoch are unresolved; do not interpret as milliseconds or seconds. Wraps modulo 65536 ticks.";
CM_ BO_ 1664 "PLACEHOLDER: signals and payload length are not defined; zero DLC is a drafting marker, not an approved transmit layout. ";
CM_ BO_ 1665 "PLACEHOLDER: signals and payload length are not defined; zero DLC is a drafting marker, not an approved transmit layout. ";
CM_ BO_ 1666 "PLACEHOLDER: signals and payload length are not defined; zero DLC is a drafting marker, not an approved transmit layout. ";
CM_ BO_ 1680 "PLACEHOLDER: signals and payload length are not defined; zero DLC is a drafting marker, not an approved transmit layout. ";
CM_ BO_ 1681 "PLACEHOLDER: signals and payload length are not defined; zero DLC is a drafting marker, not an approved transmit layout. ";
BA_DEF_ SG_  "ValueTable" STRING ;
BA_DEF_ BO_  "LayoutPending" INT 0 1;
BA_DEF_ BO_  "ProtocolSource" STRING ;
BA_DEF_  "BusType" STRING ;
BA_DEF_  "DBName" STRING ;
BA_DEF_ BO_  "VFrameFormat" ENUM  "StandardCAN","ExtendedCAN","reserved","J1939PG","reserved","reserved","reserved","reserved","reserved","reserved","reserved","reserved","reserved","reserved","StandardCAN_FD","ExtendedCAN_FD";
BA_DEF_ BO_  "CANFD_BRS" ENUM  "0","1";
BA_DEF_ BO_  "GenMsgSendType" ENUM  "Cyclic","Triggered","None";
BA_DEF_ BO_  "GenMsgCycleTime" INT 0 65535;
BA_DEF_  "Baudrate" INT 1 10000000;
BA_DEF_  "DataBaudrate" INT 1 10000000;
BA_DEF_DEF_  "ValueTable" "";
BA_DEF_DEF_  "LayoutPending" 0;
BA_DEF_DEF_  "ProtocolSource" "";
BA_DEF_DEF_  "BusType" "CAN";
BA_DEF_DEF_  "DBName" "";
BA_DEF_DEF_  "VFrameFormat" "StandardCAN";
BA_DEF_DEF_  "CANFD_BRS" "0";
BA_DEF_DEF_  "GenMsgSendType" "Cyclic";
BA_DEF_DEF_  "GenMsgCycleTime" 0;
BA_ "BusType" "CAN FD";
BA_ "DBName" "DAqCAN";
BA_ "Baudrate" 1000000;
BA_ "DataBaudrate" 1000000;
BA_ "ProtocolSource" BO_ 1568 "Legacy calibrated HighNoon DAqCAN / TelemLeader_Center";
BA_ "VFrameFormat" BO_ 1568 14;
BA_ "GenMsgCycleTime" BO_ 1568 10;
BA_ "ProtocolSource" BO_ 1569 "2027 allocation draft";
BA_ "VFrameFormat" BO_ 1569 14;
BA_ "GenMsgCycleTime" BO_ 1569 500;
BA_ "ValueTable" SG_ 1569 ServerConnected "ServerConnection";
BA_ "ValueTable" SG_ 1569 InternetConnected "Connection";
BA_ "ValueTable" SG_ 1569 Roaming "OnOff";
BA_ "ValueTable" SG_ 1569 CellularTechnology "CellularTechnology";
BA_ "ValueTable" SG_ 1569 CellularConnected "Connection";
BA_ "ProtocolSource" BO_ 1570 "2027 allocation draft";
BA_ "VFrameFormat" BO_ 1570 14;
BA_ "GenMsgCycleTime" BO_ 1570 200;
BA_ "ValueTable" SG_ 1570 GPSFix "GPSFix";
BA_ "ValueTable" SG_ 1570 GPSAntennaState "GPSAntennaState";
BA_ "ProtocolSource" BO_ 1571 "2027 allocation draft";
BA_ "VFrameFormat" BO_ 1571 14;
BA_ "GenMsgCycleTime" BO_ 1571 100;
BA_ "ValueTable" SG_ 1571 MPPTInterfaceWatchdog "Watchdog";
BA_ "ValueTable" SG_ 1571 LVCWatchdog "Watchdog";
BA_ "ValueTable" SG_ 1571 PDUWatchdog "Watchdog";
BA_ "ValueTable" SG_ 1571 PedalsWatchdog "Watchdog";
BA_ "ValueTable" SG_ 1571 DEIWatchdog "Watchdog";
BA_ "ValueTable" SG_ 1571 VCUWatchdog "Watchdog";
BA_ "ValueTable" SG_ 1571 BPSWatchdog "Watchdog";
BA_ "ProtocolSource" BO_ 1584 "2027 four-sample DAQ plan approved 2026-10-23";
BA_ "VFrameFormat" BO_ 1584 14;
BA_ "GenMsgCycleTime" BO_ 1584 20;
BA_ "ProtocolSource" BO_ 1585 "2027 four-sample DAQ plan approved 2026-10-23";
BA_ "VFrameFormat" BO_ 1585 14;
BA_ "GenMsgCycleTime" BO_ 1585 20;
BA_ "ProtocolSource" BO_ 1586 "2027 four-sample DAQ plan approved 2026-10-23";
BA_ "VFrameFormat" BO_ 1586 14;
BA_ "GenMsgCycleTime" BO_ 1586 40;
BA_ "ProtocolSource" BO_ 1600 "2027 four-sample DAQ plan approved 2026-10-23";
BA_ "VFrameFormat" BO_ 1600 14;
BA_ "GenMsgCycleTime" BO_ 1600 20;
BA_ "ProtocolSource" BO_ 1601 "2027 four-sample DAQ plan approved 2026-10-23";
BA_ "VFrameFormat" BO_ 1601 14;
BA_ "GenMsgCycleTime" BO_ 1601 20;
BA_ "ProtocolSource" BO_ 1602 "2027 four-sample DAQ plan approved 2026-10-23";
BA_ "VFrameFormat" BO_ 1602 14;
BA_ "GenMsgCycleTime" BO_ 1602 20;
BA_ "ProtocolSource" BO_ 1616 "2027 four-sample DAQ plan approved 2026-10-23";
BA_ "VFrameFormat" BO_ 1616 14;
BA_ "GenMsgCycleTime" BO_ 1616 20;
BA_ "ProtocolSource" BO_ 1617 "2027 four-sample DAQ plan approved 2026-10-23";
BA_ "VFrameFormat" BO_ 1617 14;
BA_ "GenMsgCycleTime" BO_ 1617 20;
BA_ "ProtocolSource" BO_ 1618 "2027 four-sample DAQ plan approved 2026-10-23";
BA_ "VFrameFormat" BO_ 1618 14;
BA_ "GenMsgCycleTime" BO_ 1618 20;
BA_ "ProtocolSource" BO_ 1632 "2027 four-sample DAQ plan approved 2026-10-23";
BA_ "VFrameFormat" BO_ 1632 14;
BA_ "GenMsgCycleTime" BO_ 1632 20;
BA_ "ProtocolSource" BO_ 1633 "2027 four-sample DAQ plan approved 2026-10-23";
BA_ "VFrameFormat" BO_ 1633 14;
BA_ "GenMsgCycleTime" BO_ 1633 20;
BA_ "ProtocolSource" BO_ 1634 "2027 four-sample DAQ plan approved 2026-10-23";
BA_ "VFrameFormat" BO_ 1634 14;
BA_ "GenMsgCycleTime" BO_ 1634 20;
BA_ "ProtocolSource" BO_ 1648 "Legacy calibrated HighNoon DAqCAN / Suspension_FR, Suspension_FL, Suspension_Back";
BA_ "VFrameFormat" BO_ 1648 14;
BA_ "GenMsgCycleTime" BO_ 1648 10;
BA_ "ProtocolSource" BO_ 1649 "Legacy calibrated HighNoon DAqCAN / Suspension_FR, Suspension_FL, Suspension_Back";
BA_ "VFrameFormat" BO_ 1649 14;
BA_ "GenMsgCycleTime" BO_ 1649 10;
BA_ "ProtocolSource" BO_ 1650 "Legacy calibrated HighNoon DAqCAN / Suspension_FR, Suspension_FL, Suspension_Back";
BA_ "VFrameFormat" BO_ 1650 14;
BA_ "GenMsgCycleTime" BO_ 1650 10;
BA_ "LayoutPending" BO_ 1664 1;
BA_ "ProtocolSource" BO_ 1664 "2027 allocation draft";
BA_ "VFrameFormat" BO_ 1664 14;
BA_ "GenMsgCycleTime" BO_ 1664 100;
BA_ "LayoutPending" BO_ 1665 1;
BA_ "ProtocolSource" BO_ 1665 "2027 allocation draft";
BA_ "VFrameFormat" BO_ 1665 14;
BA_ "GenMsgCycleTime" BO_ 1665 100;
BA_ "LayoutPending" BO_ 1666 1;
BA_ "ProtocolSource" BO_ 1666 "2027 allocation draft";
BA_ "VFrameFormat" BO_ 1666 14;
BA_ "GenMsgCycleTime" BO_ 1666 100;
BA_ "LayoutPending" BO_ 1680 1;
BA_ "ProtocolSource" BO_ 1680 "2027 allocation draft";
BA_ "VFrameFormat" BO_ 1680 14;
BA_ "GenMsgCycleTime" BO_ 1680 10;
BA_ "LayoutPending" BO_ 1681 1;
BA_ "ProtocolSource" BO_ 1681 "2027 allocation draft";
BA_ "VFrameFormat" BO_ 1681 14;
BA_ "GenMsgCycleTime" BO_ 1681 10;
VAL_ 1569 ServerConnected 0 "Disconnected/Retrying" 1 "Connected" ;
VAL_ 1569 InternetConnected 0 "Disconnected" 1 "Connected" ;
VAL_ 1569 Roaming 0 "Off" 1 "On" ;
VAL_ 1569 CellularTechnology 0 "None" 1 "LTE" 2 "LTE_M" 3 "NB_IoT" 4 "Other" ;
VAL_ 1569 CellularConnected 0 "Disconnected" 1 "Connected" ;
VAL_ 1570 GPSFix 0 "NoFix" 1 "Fix2D" 2 "Fix3D" ;
VAL_ 1570 GPSAntennaState 0 "OK" 1 "OpenCircuit" 2 "ShortCircuit" 3 "Unknown" ;
VAL_ 1571 MPPTInterfaceWatchdog 0 "Alive" 1 "TimedOut" ;
VAL_ 1571 LVCWatchdog 0 "Alive" 1 "TimedOut" ;
VAL_ 1571 PDUWatchdog 0 "Alive" 1 "TimedOut" ;
VAL_ 1571 PedalsWatchdog 0 "Alive" 1 "TimedOut" ;
VAL_ 1571 DEIWatchdog 0 "Alive" 1 "TimedOut" ;
VAL_ 1571 VCUWatchdog 0 "Alive" 1 "TimedOut" ;
VAL_ 1571 BPSWatchdog 0 "Alive" 1 "TimedOut" ;
